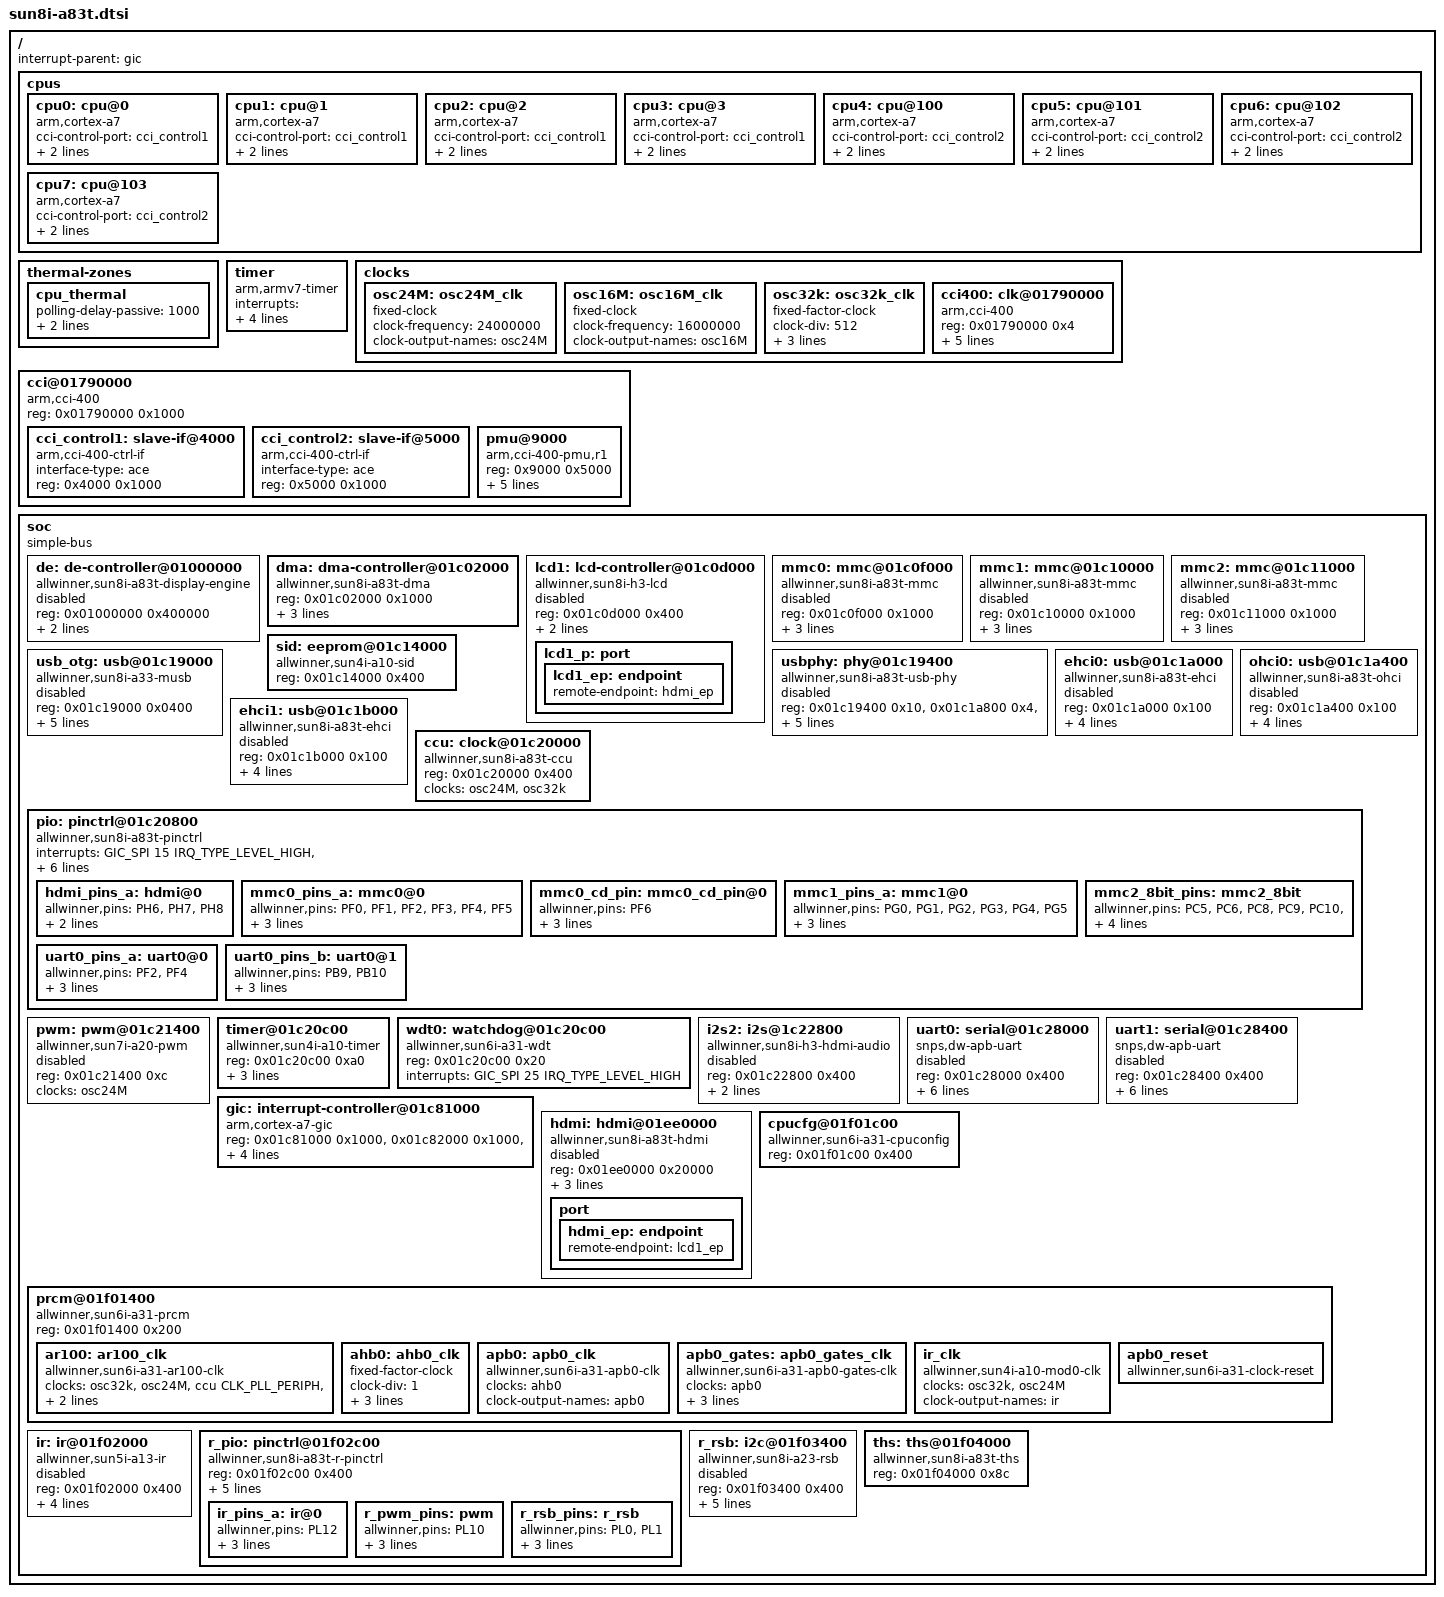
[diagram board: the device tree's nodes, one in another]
/*
 * Copyright 2015 Vishnu Patekar
 *
 * Vishnu Patekar <vishnupatekar0510@gmail.com>
 *
 * This file is dual-licensed: you can use it either under the terms
 * of the GPL or the X11 license, at your option. Note that this dual
 * licensing only applies to this file, and not this project as a
 * whole.
 *
 *  a) This file is free software; you can redistribute it and/or
 *     modify it under the terms of the GNU General Public License as
 *     published by the Free Software Foundation; either version 2 of the
 *     License, or (at your option) any later version.
 *
 *     This file is distributed in the hope that it will be useful,
 *     but WITHOUT ANY WARRANTY; without even the implied warranty of
 *     MERCHANTABILITY or FITNESS FOR A PARTICULAR PURPOSE.  See the
 *     GNU General Public License for more details.
 *
 * Or, alternatively,
 *
 *  b) Permission is hereby granted, free of charge, to any person
 *     obtaining a copy of this software and associated documentation
 *     files (the "Software"), to deal in the Software without
 *     restriction, including without limitation the rights to use,
 *     copy, modify, merge, publish, distribute, sublicense, and/or
 *     sell copies of the Software, and to permit persons to whom the
 *     Software is furnished to do so, subject to the following
 *     conditions:
 *
 *     The above copyright notice and this permission notice shall be
 *     included in all copies or substantial portions of the Software.
 *
 *     THE SOFTWARE IS PROVIDED "AS IS", WITHOUT WARRANTY OF ANY KIND,
 *     EXPRESS OR IMPLIED, INCLUDING BUT NOT LIMITED TO THE WARRANTIES
 *     OF MERCHANTABILITY, FITNESS FOR A PARTICULAR PURPOSE AND
 *     NONINFRINGEMENT. IN NO EVENT SHALL THE AUTHORS OR COPYRIGHT
 *     HOLDERS BE LIABLE FOR ANY CLAIM, DAMAGES OR OTHER LIABILITY,
 *     WHETHER IN AN ACTION OF CONTRACT, TORT OR OTHERWISE, ARISING
 *     FROM, OUT OF OR IN CONNECTION WITH THE SOFTWARE OR THE USE OR
 *     OTHER DEALINGS IN THE SOFTWARE.
 */

#include "skeleton.dtsi"

#include <dt-bindings/clock/sun8i-a83t.h>
#include <dt-bindings/interrupt-controller/arm-gic.h>
#include <dt-bindings/pinctrl/sun4i-a10.h>
#include <dt-bindings/reset/sun8i-a83t.h>
#include <dt-bindings/pwm/pwm.h>

/ {
	interrupt-parent = <&gic>;

	cpus {
		#address-cells = <1>;
		#size-cells = <0>;
//		enable-method = "allwinner,sun6i-a31";

		cpu0: cpu@0 {
			compatible = "arm,cortex-a7";
			device_type = "cpu";
			cci-control-port = <&cci_control1>;
			clock-frequency = <12000000>;
			reg = <0x0>;
//			clocks = <&cpus>;
//			clock-latency = <244144>; /* 8 32k periods */
//			operating-points = <
//				/* kHz    uV */
//				1200000 1400000
//				1008000 1400000
//				912000	1400000
//				864000  1350000
//				720000  1250000
//				528000  1150000
//				432000	1100000
//				>;
//			#cooling-cells = <2>;
//			cooling-min-level = <0>;
//			cooling-max-level = <3>;
		};

		cpu1: cpu@1 {
			compatible = "arm,cortex-a7";
			device_type = "cpu";
			cci-control-port = <&cci_control1>;
			clock-frequency = <12000000>;
			reg = <0x1>;
//			clocks = <&cpus>;
		};

		cpu2: cpu@2 {
			compatible = "arm,cortex-a7";
			device_type = "cpu";
			cci-control-port = <&cci_control1>;
			clock-frequency = <12000000>;
			reg = <0x2>;
//			clocks = <&cpus>;
		};

		cpu3: cpu@3 {
			compatible = "arm,cortex-a7";
			device_type = "cpu";
			cci-control-port = <&cci_control1>;
			clock-frequency = <12000000>;
			reg = <0x3>;
//			clocks = <&cpus>;
		};

		cpu4: cpu@100 {
			compatible = "arm,cortex-a7";
			device_type = "cpu";
			cci-control-port = <&cci_control2>;
			clock-frequency = <12000000>;
			reg = <0x100>;
//			clocks = <&cpus>;
//			clock-latency = <244144>; /* 8 32k periods */
//			operating-points = <
//				/* kHz    uV */
//				1200000 1400000
//				1008000 1400000
//				912000	1400000
//				864000  1350000
//				720000  1250000
//				528000  1150000
//				432000	1100000
//				>;
//			#cooling-cells = <2>;
//			cooling-min-level = <0>;
//			cooling-max-level = <3>;
		};

		cpu5: cpu@101 {
			compatible = "arm,cortex-a7";
			device_type = "cpu";
			cci-control-port = <&cci_control2>;
			clock-frequency = <12000000>;
			reg = <0x101>;
//			clocks = <&cpus>;
		};

		cpu6: cpu@102 {
			compatible = "arm,cortex-a7";
			device_type = "cpu";
			cci-control-port = <&cci_control2>;
			clock-frequency = <12000000>;
			reg = <0x102>;
//			clocks = <&cpus>;
		};

		cpu7: cpu@103 {
			compatible = "arm,cortex-a7";
			device_type = "cpu";
			cci-control-port = <&cci_control2>;
			clock-frequency = <12000000>;
			reg = <0x103>;
//			clocks = <&cpus>;
		};
	};

	thermal-zones {
		cpu_thermal: cpu_thermal {
			polling-delay-passive = <1000>;
			polling-delay = <5000>;
			thermal-sensors = <&ths 0>;
		};
	};

//	memory {
//		reg = <0x40000000 0x80000000>;
//	};

	timer {
		compatible = "arm,armv7-timer";
		interrupts = <GIC_PPI 13 (GIC_CPU_MASK_SIMPLE(8) | IRQ_TYPE_LEVEL_LOW)>,
			     <GIC_PPI 14 (GIC_CPU_MASK_SIMPLE(8) | IRQ_TYPE_LEVEL_LOW)>,
			     <GIC_PPI 11 (GIC_CPU_MASK_SIMPLE(8) | IRQ_TYPE_LEVEL_LOW)>,
			     <GIC_PPI 10 (GIC_CPU_MASK_SIMPLE(8) | IRQ_TYPE_LEVEL_LOW)>;
//		clock-frequency = <24000000>;
//		arm,cpu-registers-not-fw-configured;
	};

	clocks {
		#address-cells = <1>;
		#size-cells = <1>;
		ranges;

		/* TODO: PRCM block has a mux for this. */
		osc24M: osc24M_clk {
			#clock-cells = <0>;
			compatible = "fixed-clock";
			clock-frequency = <24000000>;
			clock-output-names = "osc24M";
		};

		/*
		 * This is called "internal OSC" in some places.
		 * It is an internal RC-based oscillator.
		 * TODO: Its controls are in the PRCM block.
		 */
		osc16M: osc16M_clk {
			#clock-cells = <0>;
			compatible = "fixed-clock";
			clock-frequency = <16000000>;
			clock-output-names = "osc16M";
		};

		osc32k: osc32k_clk {
			#clock-cells = <0>;
			compatible = "fixed-factor-clock";
			clock-div = <512>;
			clock-mult = <1>;
			clocks = <&osc16M>;
			clock-output-names = "osc32k";
		};

		cci400: clk@01790000 {
			#clock-cells = <0>;
			compatible = "arm,cci-400";
			reg = <0x01790000 0x4>;
			clocks = <&osc24M>,
			         <&ccu CLK_PLL_PERIPH>,
				 <&ccu CLK_PLL_HSIC>;
			clock-output-names = "cci400";
			assigned-clocks = <&cci400>;
			assigned-clock-parents = <&ccu CLK_PLL_PERIPH>;
		};

//		cpus: cpu_clk@01f01400 {
//			compatible = "allwinner,sun4i-a10-cpu-clk";
//			compatible = "allwinner,sun9i-a80-cpus-clk";
//			reg = <0x01f01400 0x4>;
//			#clock-cells = <0>;
//			clocks = <&osc32k>, <&osc24M>,
//			         <&ccu CLK_PLL_PERIPH>, <&osc16M>;
//			clock-output-names = "cpus";
//		};
	};

	cci@01790000 {
		compatible = "arm,cci-400";
		#address-cells = <1>;
		#size-cells = <1>;
		reg = <0x01790000 0x1000>;
		ranges = <0x0 0x01790000 0x10000>;

		cci_control1: slave-if@4000 {
			compatible = "arm,cci-400-ctrl-if";
			interface-type = "ace";
			reg = <0x4000 0x1000>;
		};

		cci_control2: slave-if@5000 {
			compatible = "arm,cci-400-ctrl-if";
			interface-type = "ace";
			reg = <0x5000 0x1000>;
		};
	
		pmu@9000 {
			compatible = "arm,cci-400-pmu,r1";
			reg = <0x9000 0x5000>;
			interrupts = <GIC_SPI 134 IRQ_TYPE_LEVEL_HIGH>,
			             <GIC_SPI 134 IRQ_TYPE_LEVEL_HIGH>,
				     <GIC_SPI 134 IRQ_TYPE_LEVEL_HIGH>,
				     <GIC_SPI 134 IRQ_TYPE_LEVEL_HIGH>,
				     <GIC_SPI 134 IRQ_TYPE_LEVEL_HIGH>;
		};
	};

	soc {
		compatible = "simple-bus";
		#address-cells = <1>;
		#size-cells = <1>;
		ranges;

		de: de-controller@01000000 {
			compatible = "allwinner,sun8i-a83t-display-engine";
			reg = <0x01000000 0x400000>;
			clocks = <&ccu CLK_PLL_DE>;
			clock-names = "clock";
			ports = <&lcd1_p>;
			status = "disabled";
		};

		dma: dma-controller@01c02000 {
			compatible = "allwinner,sun8i-a83t-dma";
//			cci-control-port = <&cci_control0>;
			reg = <0x01c02000 0x1000>;
			interrupts = <GIC_SPI 50 IRQ_TYPE_LEVEL_HIGH>;
			clocks = <&ccu CLK_BUS_DMA>;
			resets = <&ccu RST_DMA>;
			#dma-cells = <1>;
		};

		lcd1: lcd-controller@01c0d000 {
			compatible = "allwinner,sun8i-h3-lcd";
			reg = <0x01c0d000 0x400>;
			clocks = <&ccu CLK_TCON1>;
			clock-names = "clock";
			interrupts = <GIC_SPI 87 IRQ_TYPE_LEVEL_HIGH>;
			status = "disabled";
			#address-cells = <1>;
			#size-cells = <0>;
			lcd1_p: port {
				lcd1_ep: endpoint {
					remote-endpoint = <&hdmi_ep>;
				};
			};
		};

		mmc0: mmc@01c0f000 {			// SD card
			compatible = "allwinner,sun8i-a83t-mmc";
			reg = <0x01c0f000 0x1000>;
			clocks = <&ccu CLK_BUS_MMC0>,
				 <&ccu CLK_MMC0>,
				 <&ccu CLK_MMC0_OUTPUT>,
				 <&ccu CLK_MMC0_SAMPLE>;
			clock-names = "ahb",
				      "mmc",
				      "output",
				      "sample";
			//reset by bus-gate
			interrupts = <GIC_SPI 60 IRQ_TYPE_LEVEL_HIGH>;
			status = "disabled";
			#address-cells = <1>;
			#size-cells = <0>;
		};

		mmc1: mmc@01c10000 {			// Wifi/BT
			compatible = "allwinner,sun8i-a83t-mmc";
			reg = <0x01c10000 0x1000>;
			clocks = <&ccu CLK_BUS_MMC1>,
				 <&ccu CLK_MMC1>,
				 <&ccu CLK_MMC1_OUTPUT>,
				 <&ccu CLK_MMC1_SAMPLE>;
			clock-names = "ahb",
				      "mmc",
				      "output",
				      "sample";
			interrupts = <GIC_SPI 61 IRQ_TYPE_LEVEL_HIGH>;
			status = "disabled";
			#address-cells = <1>;
			#size-cells = <0>;
		};

		mmc2: mmc@01c11000 {			// eMMC
			compatible = "allwinner,sun8i-a83t-mmc";
			reg = <0x01c11000 0x1000>;
			clocks = <&ccu CLK_BUS_MMC2>,
				 <&ccu CLK_MMC2>,
				 <&ccu CLK_MMC2_OUTPUT>,
				 <&ccu CLK_MMC2_SAMPLE>;
			clock-names = "ahb",
				      "mmc",
				      "output",
				      "sample";
			interrupts = <GIC_SPI 62 IRQ_TYPE_LEVEL_HIGH>;
			status = "disabled";
			#address-cells = <1>;
			#size-cells = <0>;
		};

		sid: eeprom@01c14000 {
			compatible = "allwinner,sun4i-a10-sid";
			reg = <0x01c14000 0x400>;
			#address-cells = <1>;
			#size-cells = <1>;
//useless if not android ?
//			ths_calibration: calib@234 {
//				reg = <0x234 0x8>;
//			};
		};

		usb_otg: usb@01c19000 {
			compatible = "allwinner,sun8i-a33-musb";
			reg = <0x01c19000 0x0400>;
			clocks = <&ccu CLK_BUS_USBDRD>;
			resets = <&ccu RST_USBDRD>;
			interrupts = <GIC_SPI 71 IRQ_TYPE_LEVEL_HIGH>;
			interrupt-names = "mc";
			phys = <&usbphy 0>;
			phy-names = "usb";
			extcon = <&usbphy 0>;
			status = "disabled";
		};

		usbphy: phy@01c19400 {
			compatible = "allwinner,sun8i-a83t-usb-phy";
			reg = <0x01c19400 0x10>,
			      <0x01c1a800 0x4>,
			      <0x01c1b800 0x4>;
			reg-names = "phy_ctrl",
				    "pmu1",
				    "pmu2";
			clocks = <&ccu CLK_USB_PHY0>,
				 <&ccu CLK_USB_PHY1>,
				 <&ccu CLK_USB_HSIC>;
			clock-names = "usb0_phy",
				      "usb1_phy",
				      "usb2_phy";
			resets = <&ccu RST_USB_PHY0>,
				 <&ccu RST_USB_PHY1>,
				 <&ccu RST_USB_HSIC>;
			reset-names = "usb0_reset",
				      "usb1_reset",
				      "usb2_reset";
			status = "disabled";
			#phy-cells = <1>;
		};

		ehci0: usb@01c1a000 {
			compatible = "allwinner,sun8i-a83t-ehci", "generic-ehci";
			reg = <0x01c1a000 0x100>;
			interrupts = <GIC_SPI 72 IRQ_TYPE_LEVEL_HIGH>;
			clocks = <&ccu CLK_BUS_EHCI0>;
			resets = <&ccu RST_EHCI0>;
			phys = <&usbphy 1>;
			phy-names = "usb";
			status = "disabled";
		};

		ohci0: usb@01c1a400 {
			compatible = "allwinner,sun8i-a83t-ohci", "generic-ohci";
			reg = <0x01c1a400 0x100>;
			interrupts = <GIC_SPI 73 IRQ_TYPE_LEVEL_HIGH>;
			clocks = <&ccu CLK_BUS_OHCI0>, <&ccu CLK_OHCI0>;
			resets = <&ccu RST_OHCI0>;
			phys = <&usbphy 1>;
			phy-names = "usb";
			status = "disabled";
		};

		ehci1: usb@01c1b000 {
			compatible = "allwinner,sun8i-a83t-ehci", "generic-ehci";
			reg = <0x01c1b000 0x100>;
			interrupts = <GIC_SPI 74 IRQ_TYPE_LEVEL_HIGH>;
			clocks = <&ccu CLK_BUS_EHCI1>, <&ccu CLK_OSC12M>;
			resets = <&ccu RST_EHCI1>;
			phys = <&usbphy 2>;
			phy-names = "usb";
			status = "disabled";
		};

		ccu: clock@01c20000 {
			compatible = "allwinner,sun8i-a83t-ccu";
			reg = <0x01c20000 0x400>;
			clocks = <&osc24M>, <&osc32k>;
			clock-names = "hosc", "losc";
			// specific clock rates set in child dts
			#clock-cells = <1>;
			#reset-cells = <1>;
		};

		pio: pinctrl@01c20800 {
			compatible = "allwinner,sun8i-a83t-pinctrl";
			interrupts = <GIC_SPI 15 IRQ_TYPE_LEVEL_HIGH>,
				     <GIC_SPI 17 IRQ_TYPE_LEVEL_HIGH>,
				     <GIC_SPI 100 IRQ_TYPE_LEVEL_HIGH>;
			reg = <0x01c20800 0x400>;
			clocks = <&ccu CLK_BUS_PIO>;
			gpio-controller;
			interrupt-controller;
			#interrupt-cells = <3>;
			#gpio-cells = <3>;

			hdmi_pins_a: hdmi@0 {
				allwinner,pins = "PH6", "PH7", "PH8";
				allwinner,function = "hdmi";
				allwinner,pull = <SUN4I_PINCTRL_NO_PULL>;
			};

			mmc0_pins_a: mmc0@0 {
				allwinner,pins = "PF0", "PF1", "PF2",
						 "PF3", "PF4", "PF5";
				allwinner,function = "mmc0";
				allwinner,drive = <SUN4I_PINCTRL_30_MA>;
				allwinner,pull = <SUN4I_PINCTRL_NO_PULL>;
			};

			mmc0_cd_pin: mmc0_cd_pin@0 {
				allwinner,pins = "PF6";
				allwinner,function = "gpio_in";
				allwinner,drive = <SUN4I_PINCTRL_10_MA>;
				allwinner,pull = <SUN4I_PINCTRL_PULL_UP>;
			};

			mmc1_pins_a: mmc1@0 {
				allwinner,pins = "PG0", "PG1", "PG2",
						 "PG3", "PG4", "PG5";
				allwinner,function = "mmc1";
				allwinner,drive = <SUN4I_PINCTRL_30_MA>;
				allwinner,pull = <SUN4I_PINCTRL_NO_PULL>;
			};

			mmc2_8bit_pins: mmc2_8bit {
				allwinner,pins = "PC5", "PC6", "PC8",
						 "PC9", "PC10", "PC11",
						 "PC12", "PC13", "PC14",
						 "PC15", "PC16";
				allwinner,function = "mmc2";
				allwinner,drive = <SUN4I_PINCTRL_30_MA>;
				allwinner,pull = <SUN4I_PINCTRL_NO_PULL>;
			};

			uart0_pins_a: uart0@0 {
				allwinner,pins = "PF2", "PF4";
				allwinner,function = "uart0";
				allwinner,drive = <SUN4I_PINCTRL_10_MA>;
				allwinner,pull = <SUN4I_PINCTRL_NO_PULL>;
			};

			uart0_pins_b: uart0@1 {
				allwinner,pins = "PB9", "PB10";
				allwinner,function = "uart0";
				allwinner,drive = <SUN4I_PINCTRL_10_MA>;
				allwinner,pull = <SUN4I_PINCTRL_NO_PULL>;
			};
		};

		pwm: pwm@01c21400 {
			compatible = "allwinner,sun7i-a20-pwm";
			reg = <0x01c21400 0xc>;
			clocks = <&osc24M>;
			#pwm-cells = <3>;
			status = "disabled";
		};

		timer@01c20c00 {
			compatible = "allwinner,sun4i-a10-timer";
			reg = <0x01c20c00 0xa0>;
			interrupts = <GIC_SPI 18 IRQ_TYPE_LEVEL_HIGH>,
				     <GIC_SPI 19 IRQ_TYPE_LEVEL_HIGH>;
			clocks = <&osc24M>;
		};

		wdt0: watchdog@01c20c00 {
			compatible = "allwinner,sun6i-a31-wdt";
			reg = <0x01c20c00 0x20>;
			interrupts = <GIC_SPI 25 IRQ_TYPE_LEVEL_HIGH>;
		};

		i2s2: i2s@1c22800 {
			compatible = "allwinner,sun8i-h3-hdmi-audio";
			reg = <0x01c22800 0x400>;
			clocks = <&ccu CLK_PLL_AUDIO>, <&ccu CLK_DAUDIO2>;
			clock-names = "clock", "i2s2";
			dmas = <&dma 27>;
			dma-names = "tx";
			status = "disabled";
		};

		uart0: serial@01c28000 {
			compatible = "snps,dw-apb-uart";
			reg = <0x01c28000 0x400>;
			interrupts = <GIC_SPI 0 IRQ_TYPE_LEVEL_HIGH>;
			reg-shift = <2>;
			reg-io-width = <4>;
			clocks = <&ccu CLK_BUS_UART0>;
			resets = <&ccu RST_UART0>;
			dmas = <&dma 6>, <&dma 6>;
			dma-names = "rx", "tx";
			status = "disabled";
		};
//fixme: more uart 2..4

		uart1: serial@01c28400 {
			compatible = "snps,dw-apb-uart";
			reg = <0x01c28400 0x400>;
			interrupts = <GIC_SPI 1 IRQ_TYPE_LEVEL_HIGH>;
			reg-shift = <2>;
			reg-io-width = <4>;
			clocks = <&ccu CLK_BUS_UART1>;
			resets = <&ccu RST_UART1>;
			dmas = <&dma 7>, <&dma 7>;
			dma-names = "rx", "tx";
			status = "disabled";
		};

		gic: interrupt-controller@01c81000 {
			compatible = "arm,cortex-a7-gic", "arm,cortex-a15-gic";
			reg = <0x01c81000 0x1000>,
			      <0x01c82000 0x1000>,
			      <0x01c84000 0x2000>,
			      <0x01c86000 0x2000>;
			interrupt-controller;
			#interrupt-cells = <3>;
			interrupts = <GIC_PPI 9 (GIC_CPU_MASK_SIMPLE(8) | IRQ_TYPE_LEVEL_HIGH)>;
		};

		hdmi: hdmi@01ee0000 {
			compatible = "allwinner,sun8i-a83t-hdmi";
			reg = <0x01ee0000 0x20000>;
			clocks = <&ccu CLK_HDMI>, <&ccu CLK_HDMI_DDC>;
			clock-names = "clock", "ddc-clock";
			resets = <&ccu RST_HDMI0>, <&ccu RST_HDMI1>;
			reset-names = "hdmi0", "hdmi1";
			pinctrl-names = "default";
			pinctrl-0 = <&hdmi_pins_a>;
			status = "disabled";
			#address-cells = <1>;
			#size-cells = <0>;
			port {
				hdmi_ep: endpoint {
					remote-endpoint = <&lcd1_ep>;
				};
			};
		};

//		rtc: rtc@01f00000 {
//			compatible = "allwinner,sun6i-a31-rtc";
//			reg = <0x01f00000 0x54>;
//			interrupts = <GIC_SPI 40 IRQ_TYPE_LEVEL_HIGH>,
//			             <GIC_SPI 41 IRQ_TYPE_LEVEL_HIGH>;
//		};
//
		cpucfg@01f01c00 {
			compatible = "allwinner,sun6i-a31-cpuconfig";
			reg = <0x01f01c00 0x400>;
		};
//
//		nmi_intc: interrupt-controller@01f00c00 {
//			compatible = "allwinner,sun6i-a31-sc-nmi";
//			reg = <0x01f01c00 0x400>;
//			interrupt-controller;
//			#interrupt-cells = <2>;
//			interrupts = <GIC_SPI 32 IRQ_TYPE_LEVEL_HIGH>;
//		};

		prcm@01f01400 {
			compatible = "allwinner,sun6i-a31-prcm";
			reg = <0x01f01400 0x200>;

			ar100: ar100_clk {
				compatible = "allwinner,sun6i-a31-ar100-clk";
				#clock-cells = <0>;
				clocks = <&osc32k>, <&osc24M>,
				         <&ccu CLK_PLL_PERIPH>,
					 <&osc16M>;
				clock-output-names = "ar100";
			};

			ahb0: ahb0_clk {
				compatible = "fixed-factor-clock";
				#clock-cells = <0>;
				clock-div = <1>;
				clock-mult = <1>;
				clocks = <&ar100>;
				clock-output-names = "ahb0";
			};

			apb0: apb0_clk {
				compatible = "allwinner,sun6i-a31-apb0-clk";
				#clock-cells = <0>;
				clocks = <&ahb0>;
				clock-output-names = "apb0";
			};

			apb0_gates: apb0_gates_clk {
				compatible = "allwinner,sun6i-a31-apb0-gates-clk";
				#clock-cells = <1>;
				clocks = <&apb0>;
				clock-output-names = "apb0_pio", "apb0_ir",
				                     "apb0_timer", "apb0_rsb",
				                     "apb0_uart", "apb0_i2c0",
						     "apb0_twd";
			};

			ir_clk: ir_clk {
				#clock-cells = <0>;
				compatible = "allwinner,sun4i-a10-mod0-clk";
				clocks = <&osc32k>, <&osc24M>;
				clock-output-names = "ir";
			};

			apb0_reset: apb0_reset {
				compatible = "allwinner,sun6i-a31-clock-reset";
				#reset-cells = <1>;
			};
		};

		ir: ir@01f02000 {
			compatible = "allwinner,sun5i-a13-ir";
			reg = <0x01f02000 0x400>;
			interrupts = <GIC_SPI 37 IRQ_TYPE_LEVEL_HIGH>;
			clocks = <&apb0_gates 1>, <&ir_clk>;
			clock-names = "apb", "ir";
			resets = <&apb0_reset 1>;
			pinctrl-names = "default";
			pinctrl-0 = <&ir_pins_a>;
			status = "disabled";
		};

		r_pio: pinctrl@01f02c00 {
			compatible = "allwinner,sun8i-a83t-r-pinctrl";
			reg = <0x01f02c00 0x400>;
			interrupts = <GIC_SPI 45 IRQ_TYPE_LEVEL_HIGH>;
			clocks = <&apb0_gates 0>;
			resets = <&apb0_reset 0>;
			gpio-controller;
			interrupt-controller;
			#interrupt-cells = <3>;
			#gpio-cells = <3>;

			ir_pins_a: ir@0 {
				allwinner,pins = "PL12";
				allwinner,function = "s_cir";
				allwinner,drive = <SUN4I_PINCTRL_10_MA>;
				allwinner,pull = <SUN4I_PINCTRL_NO_PULL>;
			};

			r_pwm_pins: pwm {
				allwinner,pins = "PL10";
				allwinner,function = "s_pwm";
				allwinner,drive = <SUN4I_PINCTRL_10_MA>;
				allwinner,pull = <SUN4I_PINCTRL_NO_PULL>;
			};

			r_rsb_pins: r_rsb {
				allwinner,pins = "PL0", "PL1";
				allwinner,function = "s_rsb";
				allwinner,drive = <SUN4I_PINCTRL_20_MA>;
				allwinner,pull = <SUN4I_PINCTRL_PULL_UP>;
			};
		};

		r_rsb: i2c@01f03400 {
			compatible = "allwinner,sun8i-a23-rsb";
			reg = <0x01f03400 0x400>;
			interrupts = <GIC_SPI 39 IRQ_TYPE_LEVEL_HIGH>;
			clocks = <&apb0_gates 3>;
			clock-frequency = <3000000>;
			resets = <&apb0_reset 3>;
			pinctrl-names = "default";
			pinctrl-0 = <&r_rsb_pins>;
			status = "disabled";
			#address-cells = <1>;
			#size-cells = <0>;
		};

		ths: ths@01f04000 {
			#thermal-sensor-cells = <0>;
			compatible = "allwinner,sun8i-a83t-ths";
			reg = <0x01f04000 0x8c>;
//fixme: irq 31 in H3 - irq in a83t UM is 73
//			interrupts = <GIC_SPI 41 IRQ_TYPE_LEVEL_HIGH>;
//useless if not android ?
//			nvmem-cells = <&r_th_calibration>;
//			nvmem-cell-names = "calibration";
		};
	};
};
